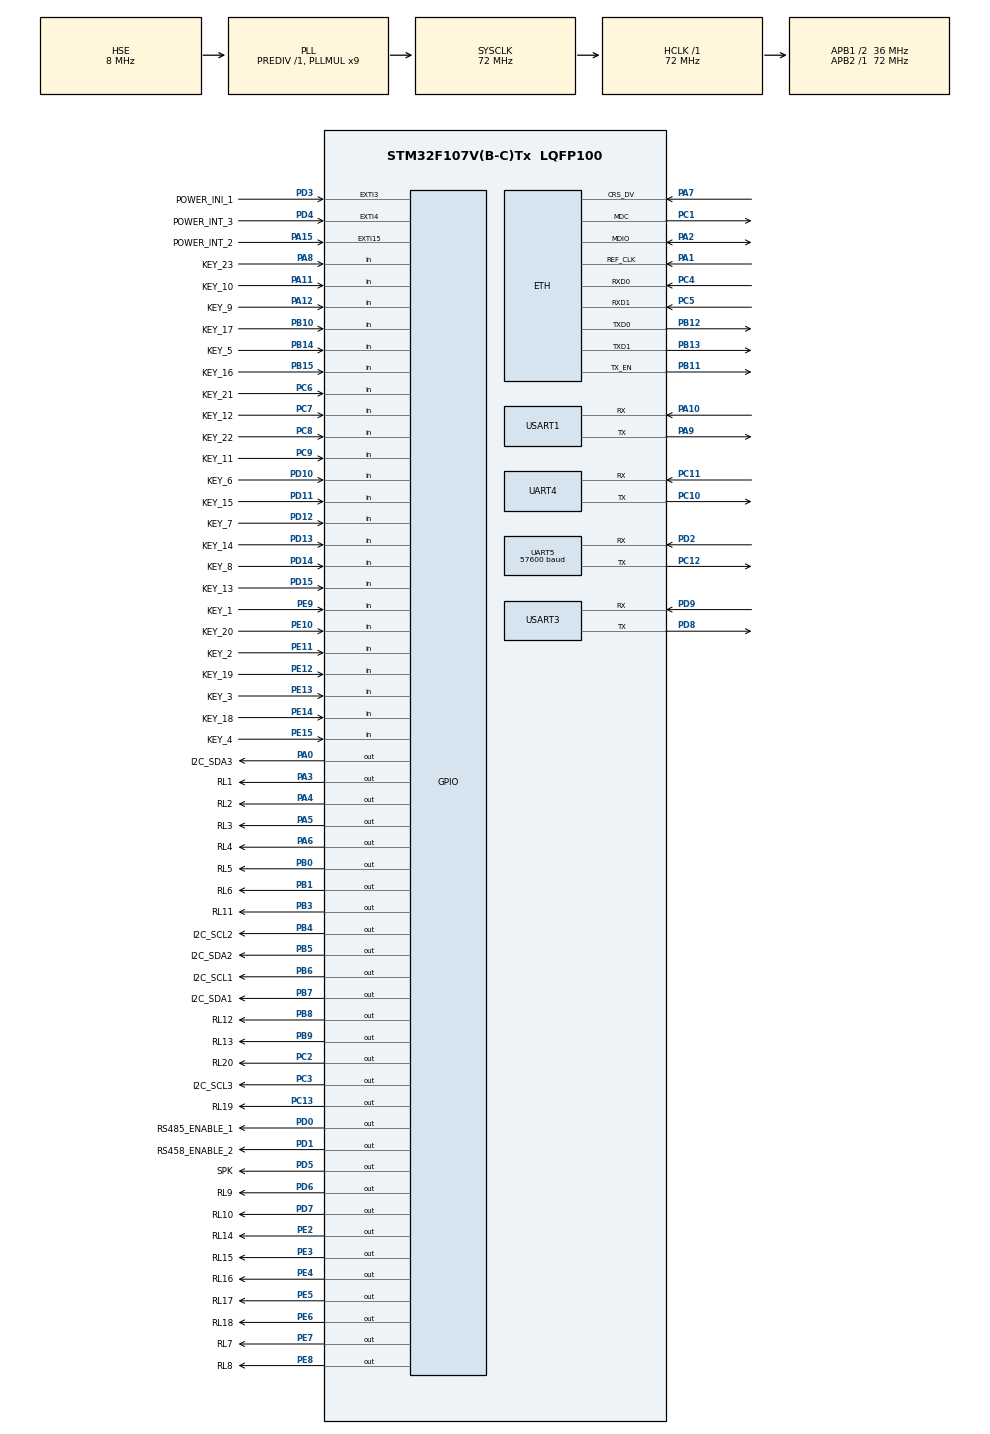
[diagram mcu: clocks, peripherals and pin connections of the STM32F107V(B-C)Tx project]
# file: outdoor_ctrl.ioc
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ETH.MediaInterface=ETH_MEDIA_INTERFACE_RMII
ETH.PhyAddress=0
FREERTOS.INCLUDE_uxTaskGetStackHighWaterMark=1
FREERTOS.INCLUDE_xTaskGetCurrentTaskHandle=1
FREERTOS.Queues01=serial_queue,8,uint8_t,NULL;socket_queue,8,uint32_t,NULL;key_queue,8,uint8_t,NULL
FREERTOS.Tasks01=system,0,200,systrm_task,Default;serial_server,2,256,serial_task,Default;socket_server,2,256,socket_server_task,Default;read_key,0,128,read_keyr_task,Default;deal_key,2,128,deal_key_task,Default
FREERTOS.configMINIMAL_STACK_SIZE=128
FREERTOS.configTOTAL_HEAP_SIZE=20480
FREERTOS.configUSE_IDLE_HOOK=1
FREERTOS.configUSE_TICK_HOOK=1
IWDG.Prescaler=IWDG_PRESCALER_16
LWIP.GATEWAY_ADDRESS=192.168.001.001
LWIP.IP_ADDRESS=192.168.001.252
LWIP.LWIP_DBG_MIN_LEVEL=LWIP_DBG_MASK_LEVEL
LWIP.LWIP_DHCP=0
LWIP.MEMP_NUM_RAW_PCB=10
LWIP.MEMP_NUM_TCP_PCB=10
LWIP.MEMP_NUM_UDP_PCB=10
LWIP.MEM_SIZE=2400
LWIP.NETMASK_ADDRESS=255.255.255.000
LWIP.TCPIP_THREAD_STACKSIZE=1024
LWIP.TCP_QUEUE_OOSEQ=0
LWIP.Version=v1.4.1_Cube
Mcu.Family=STM32F1
Mcu.Name=STM32F107V(B-C)Tx
Mcu.Package=LQFP100
NVIC.ETH_IRQn=true\:5\:0\:false\:false\:true\:true
NVIC.ETH_WKUP_IRQn=true\:5\:0\:false\:false\:true\:true
NVIC.EXTI15_10_IRQn=true\:5\:0\:false\:false\:true\:true
NVIC.EXTI3_IRQn=true\:5\:0\:false\:false\:true\:true
NVIC.EXTI4_IRQn=true\:5\:0\:false\:false\:true\:true
NVIC.PriorityGroup=NVIC_PRIORITYGROUP_4
NVIC.TIM7_IRQn=true\:0\:0\:false\:false\:true\:false
NVIC.TimeBase=TIM7_IRQn
NVIC.TimeBaseIP=TIM7
NVIC.UART5_IRQn=true\:5\:0\:false\:false\:true\:true
NVIC.USART1_IRQn=true\:5\:0\:false\:false\:true\:true
OSC_IN.Mode=HSE-External-Oscillator
OSC_IN.Signal=RCC_OSC_IN
OSC_OUT.Mode=HSE-External-Oscillator
OSC_OUT.Signal=RCC_OSC_OUT
PA0-WKUP.GPIO_Label=I2C_SDA3
PA0-WKUP.GPIO_ModeDefaultOutputPP=GPIO_MODE_OUTPUT_OD
PA0-WKUP.GPIO_Speed=GPIO_SPEED_FREQ_MEDIUM
PA0-WKUP.PinState=GPIO_PIN_SET
PA0-WKUP.Signal=GPIO_Output
PA1.Mode=RMII
PA1.Signal=ETH_REF_CLK
PA10.Mode=Asynchronous
PA10.Signal=USART1_RX
PA11.GPIO_Label=KEY_10
PA11.Signal=GPIO_Input
PA12.GPIO_Label=KEY_9
PA12.Signal=GPIO_Input
PA13.Mode=Serial_Wire
PA13.Signal=SYS_JTMS-SWDIO
PA14.Mode=Serial_Wire
PA14.Signal=SYS_JTCK-SWCLK
PA15.GPIO_Label=POWER_INT_2
PA15.GPIO_ModeDefaultEXTI=GPIO_MODE_IT_RISING
PA15.Signal=GPXTI15
PA2.Mode=RMII
PA2.Signal=ETH_MDIO
PA3.GPIO_Label=RL1
PA3.Signal=GPIO_Output
PA4.GPIO_Label=RL2
PA4.Signal=GPIO_Output
PA5.GPIO_Label=RL3
PA5.Signal=GPIO_Output
PA6.GPIO_Label=RL4
PA6.Signal=GPIO_Output
PA7.Mode=RMII
PA7.Signal=ETH_CRS_DV
PA8.GPIO_Label=KEY_23
PA8.Signal=GPIO_Input
PA9.Mode=Asynchronous
PA9.Signal=USART1_TX
PB0.GPIO_Label=RL5
PB0.Signal=GPIO_Output
PB1.GPIO_Label=RL6
PB1.Signal=GPIO_Output
PB10.GPIO_Label=KEY_17
PB10.Signal=GPIO_Input
PB11.Mode=RMII
PB11.Signal=ETH_TX_EN
PB12.Mode=RMII
PB12.Signal=ETH_TXD0
PB13.Mode=RMII
PB13.Signal=ETH_TXD1
PB14.GPIO_Label=KEY_5
PB14.Signal=GPIO_Input
PB15.GPIO_Label=KEY_16
PB15.Signal=GPIO_Input
PB3.GPIO_Label=RL11
PB3.Signal=GPIO_Output
PB4.GPIO_Label=I2C_SCL2
PB4.PinState=GPIO_PIN_SET
PB4.Signal=GPIO_Output
PB5.GPIO_Label=I2C_SDA2
PB5.GPIO_ModeDefaultOutputPP=GPIO_MODE_OUTPUT_OD
PB5.PinState=GPIO_PIN_SET
PB5.Signal=GPIO_Output
PB6.GPIO_Label=I2C_SCL1
PB6.PinState=GPIO_PIN_SET
PB6.Signal=GPIO_Output
PB7.GPIO_Label=I2C_SDA1
PB7.GPIO_ModeDefaultOutputPP=GPIO_MODE_OUTPUT_OD
PB7.PinState=GPIO_PIN_SET
PB7.Signal=GPIO_Output
PB8.GPIO_Label=RL12
PB8.Signal=GPIO_Output
PB9.GPIO_Label=RL13
PB9.Signal=GPIO_Output
PC1.Mode=RMII
PC1.Signal=ETH_MDC
PC10.Mode=Asynchronous
PC10.Signal=UART4_TX
PC11.Mode=Asynchronous
PC11.Signal=UART4_RX
PC12.Mode=Asynchronous
PC12.Signal=UART5_TX
PC13-TAMPER-RTC.GPIO_Label=RL19
PC13-TAMPER-RTC.Signal=GPIO_Output
PC14-OSC32_IN.Mode=LSE-External-Oscillator
PC14-OSC32_IN.Signal=RCC_OSC32_IN
PC15-OSC32_OUT.Mode=LSE-External-Oscillator
PC15-OSC32_OUT.Signal=RCC_OSC32_OUT
PC2.GPIO_Label=RL20
PC2.Signal=GPIO_Output
PC3.GPIO_Label=I2C_SCL3
PC3.PinState=GPIO_PIN_SET
PC3.Signal=GPIO_Output
PC4.Mode=RMII
PC4.Signal=ETH_RXD0
PC5.Mode=RMII
PC5.Signal=ETH_RXD1
PC6.GPIO_Label=KEY_21
PC6.Signal=GPIO_Input
PC7.GPIO_Label=KEY_12
PC7.Signal=GPIO_Input
PC8.GPIO_Label=KEY_22
PC8.Signal=GPIO_Input
PC9.GPIO_Label=KEY_11
PC9.Signal=GPIO_Input
PD0.GPIO_Label=RS485_ENABLE_1
PD0.Signal=GPIO_Output
PD1.GPIO_Label=RS458_ENABLE_2
PD1.Signal=GPIO_Output
PD10.GPIO_Label=KEY_6
PD10.Signal=GPIO_Input
PD11.GPIO_Label=KEY_15
PD11.Signal=GPIO_Input
PD12.GPIO_Label=KEY_7
PD12.Signal=GPIO_Input
PD13.GPIO_Label=KEY_14
PD13.Signal=GPIO_Input
PD14.GPIO_Label=KEY_8
PD14.Signal=GPIO_Input
PD15.GPIO_Label=KEY_13
PD15.Signal=GPIO_Input
PD2.Mode=Asynchronous
PD2.Signal=UART5_RX
PD3.GPIO_Label=POWER_INI_1
PD3.Signal=GPXTI3
PD4.GPIO_Label=POWER_INT_3
PD4.Signal=GPXTI4
PD5.GPIO_Label=SPK
PD5.Signal=GPIO_Output
PD6.GPIO_Label=RL9
PD6.Signal=GPIO_Output
PD7.GPIO_Label=RL10
PD7.Signal=GPIO_Output
PD8.Mode=Asynchronous
PD8.Signal=USART3_TX
PD9.Mode=Asynchronous
PD9.Signal=USART3_RX
PE10.GPIO_Label=KEY_20
PE10.Signal=GPIO_Input
PE11.GPIO_Label=KEY_2
PE11.Signal=GPIO_Input
PE12.GPIO_Label=KEY_19
PE12.Signal=GPIO_Input
PE13.GPIO_Label=KEY_3
PE13.Signal=GPIO_Input
PE14.GPIO_Label=KEY_18
PE14.Signal=GPIO_Input
PE15.GPIO_Label=KEY_4
PE15.Signal=GPIO_Input
PE2.GPIO_Label=RL14
PE2.Signal=GPIO_Output
PE3.GPIO_Label=RL15
PE3.Signal=GPIO_Output
PE4.GPIO_Label=RL16
PE4.Signal=GPIO_Output
PE5.GPIO_Label=RL17
PE5.Signal=GPIO_Output
PE6.GPIO_Label=RL18
PE6.Signal=GPIO_Output
PE7.GPIO_Label=RL7
PE7.Signal=GPIO_Output
PE8.GPIO_Label=RL8
PE8.Signal=GPIO_Output
PE9.GPIO_Label=KEY_1
PE9.Signal=GPIO_Input
ProjectManager.HeapSize=0x1000
ProjectManager.StackSize=0x800
ProjectManager.TargetToolchain=MDK-ARM V5
RCC.AHBFreq_Value=72000000
RCC.APB1CLKDivider=RCC_HCLK_DIV2
RCC.APB1Freq_Value=36000000
RCC.APB1TimFreq_Value=72000000
RCC.APB2Freq_Value=72000000
RCC.APB2TimFreq_Value=72000000
RCC.HCLKFreq_Value=72000000
RCC.HSIState=RCC_HSI_ON
RCC.PLLMUL=RCC_PLL_MUL9
RCC.PLLSourceVirtual=RCC_PLLSOURCE_HSE
RCC.SYSCLKFreq_VALUE=72000000
RCC.SYSCLKSource=RCC_SYSCLKSOURCE_PLLCLK
RCC.USBFreq_Value=48000000
TIM1.Period=999
TIM1.Prescaler=71
TIM2.Period=999
TIM2.Prescaler=72
TIM3.Period=999
TIM3.Prescaler=71
TIM4.Period=999
TIM4.Prescaler=71
TIM5.CounterMode=TIM_COUNTERMODE_DOWN
TIM5.Period=999
TIM5.Prescaler=71
TIM6.Period=999
TIM6.Prescaler=71
UART5.BaudRate=57600
VP_FREERTOS_VS_ENABLE.Mode=Enabled
VP_IWDG_VS_IWDG.Mode=IWDG_Activate
VP_LWIP_VS_Enabled.Mode=Enabled
VP_SYS_VS_tim7.Mode=TIM7
VP_TIM1_VS_ClockSourceINT.Mode=Internal
VP_TIM2_VS_ClockSourceINT.Mode=Internal
VP_TIM3_VS_ClockSourceINT.Mode=Internal
VP_TIM4_VS_ClockSourceINT.Mode=Internal
VP_TIM5_VS_ClockSourceINT.Mode=Internal
VP_TIM6_VS_ClockSourceINT.Mode=Enable_Timer
board=outdoor_ctrl

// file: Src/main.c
/**
  ******************************************************************************
  * File Name          : main.c
  * Description        : Main program body
  ******************************************************************************
  *
  * COPYRIGHT(c) 2017 STMicroelectronics
  *
  * Redistribution and use in source and binary forms, with or without modification,
  * are permitted provided that the following conditions are met:
  *   1. Redistributions of source code must retain the above copyright notice,
  *      this list of conditions and the following disclaimer.
  *   2. Redistributions in binary form must reproduce the above copyright notice,
  *      this list of conditions and the following disclaimer in the documentation
  *      and/or other materials provided with the distribution.
  *   3. Neither the name of STMicroelectronics nor the names of its contributors
  *      may be used to endorse or promote products derived from this software
  *      without specific prior written permission.
  *
  * THIS SOFTWARE IS PROVIDED BY THE COPYRIGHT HOLDERS AND CONTRIBUTORS "AS IS"
  * AND ANY EXPRESS OR IMPLIED WARRANTIES, INCLUDING, BUT NOT LIMITED TO, THE
  * IMPLIED WARRANTIES OF MERCHANTABILITY AND FITNESS FOR A PARTICULAR PURPOSE ARE
  * DISCLAIMED. IN NO EVENT SHALL THE COPYRIGHT HOLDER OR CONTRIBUTORS BE LIABLE
  * FOR ANY DIRECT, INDIRECT, INCIDENTAL, SPECIAL, EXEMPLARY, OR CONSEQUENTIAL
  * DAMAGES (INCLUDING, BUT NOT LIMITED TO, PROCUREMENT OF SUBSTITUTE GOODS OR
  * SERVICES; LOSS OF USE, DATA, OR PROFITS; OR BUSINESS INTERRUPTION) HOWEVER
  * CAUSED AND ON ANY THEORY OF LIABILITY, WHETHER IN CONTRACT, STRICT LIABILITY,
  * OR TORT (INCLUDING NEGLIGENCE OR OTHERWISE) ARISING IN ANY WAY OUT OF THE USE
  * OF THIS SOFTWARE, EVEN IF ADVISED OF THE POSSIBILITY OF SUCH DAMAGE.
  *
  ******************************************************************************
  */
#include "stm32f1xx_hal.h"
#include "cmsis_os.h"
#include "iwdg.h"
#include "lwip.h"
#include "tim.h"
#include "usart.h"
#include "gpio.h"

/* USER CODE BEGIN Includes */
#include "include.h"
/* USER CODE END Includes */

/* USER CODE BEGIN PV */
/* Private variables ---------------------------------------------------------*/

/* USER CODE END PV */

void SystemClock_Config(void);
void Error_Handler(void);
void MX_FREERTOS_Init(void);

/* USER CODE BEGIN PFP */
/* Private function prototypes -----------------------------------------------*/

#define COM huart1  //重定向到串口

#ifdef __GNUC__
  /* With GCC/RAISONANCE, small printf (option LD Linker->Libraries->Small printf
     set to 'Yes') calls __io_putchar() */
  #define PUTCHAR_PROTOTYPE int __io_putchar(int ch)
#else
  #define PUTCHAR_PROTOTYPE int fputc(int ch, FILE *f)
#endif /* __GNUC__ */
/**
  * @brief  Retargets the C library printf function to the USART.
  * @param  None
  * @retval None
  */
PUTCHAR_PROTOTYPE
{
  /* Place your implementation of fputc here */
  /* e.g. write a character to the EVAL_COM1 and Loop until the end of transmission */
  HAL_UART_Transmit(&COM, (unsigned char *)&ch, 1, 0xFFFF);

  return ch;
}

void test_timer_call_back(void* arg)
{
	unsigned int num;
	num = (int)arg;
	printf("timer %d over flow\n\r",num);
}
/* USER CODE END PFP */

/* USER CODE BEGIN 0 */
unsigned int phyreg;
/* USER CODE END 0 */

int main(void)
{

  /* MCU Configuration----------------------------------------------------------*/

  /* Reset of all peripherals, Initializes the Flash interface and the Systick. */
  HAL_Init();

  /* Configure the system clock */
  SystemClock_Config();

  /* Initialize all configured peripherals */
  MX_GPIO_Init();
  MX_UART4_Init();
  MX_UART5_Init();
  MX_USART1_UART_Init();
  MX_USART3_UART_Init();
  MX_IWDG_Init();
  MX_TIM1_Init();
  MX_TIM2_Init();
  MX_TIM3_Init();
  MX_TIM4_Init();
  MX_TIM5_Init();
  MX_TIM6_Init();

  /* USER CODE BEGIN 2 */
	//HAL_ETH_ReadPHYRegister(&heth, 0, &phyreg);
	//HAL_ETH_ReadPHYRegister(&heth, 1, &phyreg);
	//HAL_ETH_ReadPHYRegister(&heth, 2, &phyreg);
	//HAL_ETH_ReadPHYRegister(&heth, 3, &phyreg);

	#if WATCH_DOG
	HAL_IWDG_Start(&hiwdg);
	#endif

	HAL_TIM_Base_Start_IT(&htim5);
	//register_value_into_timer(2000,1);
	register_callback_function_into_timer(register_value_into_timer(2000,1),test_timer_call_back);
	register_value_into_timer(1000,1);
	register_value_into_timer(1000,0);
	timer_free(1);
	register_value_into_timer(3000,0);
	register_value_into_timer(5000,1);

	register_callback_function_into_timer(register_value_into_timer(3000,1),test_timer_call_back);

	register_callback_function_into_timer(register_value_into_timer(2000,1),test_timer_call_back);

	register_callback_function_into_timer(register_value_into_timer(1000,1),test_timer_call_back);

  /* USER CODE END 2 */

  /* Call init function for freertos objects (in freertos.c) */
  MX_FREERTOS_Init();

  /* Start scheduler */
  osKernelStart();

  /* We should never get here as control is now taken by the scheduler */

  /* Infinite loop */
  while (1)
  {

  /* USER CODE BEGIN 3 */
  //MX_LWIP_Process();

  }
  /* USER CODE END 3 */

}

/** System Clock Configuration
*/
void SystemClock_Config(void)
{

  RCC_OscInitTypeDef RCC_OscInitStruct;
  RCC_ClkInitTypeDef RCC_ClkInitStruct;

  RCC_OscInitStruct.OscillatorType = RCC_OSCILLATORTYPE_LSI|RCC_OSCILLATORTYPE_HSE;
  RCC_OscInitStruct.HSEState = RCC_HSE_ON;
  RCC_OscInitStruct.HSEPredivValue = RCC_HSE_PREDIV_DIV1;
  RCC_OscInitStruct.LSIState = RCC_LSI_ON;
  RCC_OscInitStruct.Prediv1Source = RCC_PREDIV1_SOURCE_HSE;
  RCC_OscInitStruct.PLL.PLLState = RCC_PLL_ON;
  RCC_OscInitStruct.PLL.PLLSource = RCC_PLLSOURCE_HSE;
  RCC_OscInitStruct.PLL.PLLMUL = RCC_PLL_MUL9;
  RCC_OscInitStruct.PLL2.PLL2State = RCC_PLL_NONE;
  if (HAL_RCC_OscConfig(&RCC_OscInitStruct) != HAL_OK)
  {
    Error_Handler();
  }

  RCC_ClkInitStruct.ClockType = RCC_CLOCKTYPE_HCLK|RCC_CLOCKTYPE_SYSCLK
                              |RCC_CLOCKTYPE_PCLK1|RCC_CLOCKTYPE_PCLK2;
  RCC_ClkInitStruct.SYSCLKSource = RCC_SYSCLKSOURCE_PLLCLK;
  RCC_ClkInitStruct.AHBCLKDivider = RCC_SYSCLK_DIV1;
  RCC_ClkInitStruct.APB1CLKDivider = RCC_HCLK_DIV2;
  RCC_ClkInitStruct.APB2CLKDivider = RCC_HCLK_DIV1;
  if (HAL_RCC_ClockConfig(&RCC_ClkInitStruct, FLASH_LATENCY_2) != HAL_OK)
  {
    Error_Handler();
  }

  HAL_SYSTICK_Config(HAL_RCC_GetHCLKFreq()/1000);

  HAL_SYSTICK_CLKSourceConfig(SYSTICK_CLKSOURCE_HCLK);

  __HAL_RCC_PLLI2S_ENABLE();

  /* SysTick_IRQn interrupt configuration */
  HAL_NVIC_SetPriority(SysTick_IRQn, 15, 0);
}

void HAL_TIM_PeriodElapsedCallback(TIM_HandleTypeDef *htim)
{
/* USER CODE BEGIN Callback 0 */

	if (htim->Instance == TIM5) {
		INC_COUNTER_TIMER();
	}
/* USER CODE END Callback 0 */
  if (htim->Instance == TIM7) {
    HAL_IncTick();
  }
}

void Error_Handler(void)
{
  while(1)
  {
  }
}

/************************ (C) COPYRIGHT STMicroelectronics *****END OF FILE****/

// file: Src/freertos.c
/**
  ******************************************************************************
  * File Name          : freertos.c
  * Description        : Code for freertos applications
  ******************************************************************************
  *
  * COPYRIGHT(c) 2017 STMicroelectronics
  *
  * Redistribution and use in source and binary forms, with or without modification,
  * are permitted provided that the following conditions are met:
  *   1. Redistributions of source code must retain the above copyright notice,
  *      this list of conditions and the following disclaimer.
  *   2. Redistributions in binary form must reproduce the above copyright notice,
  *      this list of conditions and the following disclaimer in the documentation
  *      and/or other materials provided with the distribution.
  *   3. Neither the name of STMicroelectronics nor the names of its contributors
  *      may be used to endorse or promote products derived from this software
  *      without specific prior written permission.
  *
  * THIS SOFTWARE IS PROVIDED BY THE COPYRIGHT HOLDERS AND CONTRIBUTORS "AS IS"
  * AND ANY EXPRESS OR IMPLIED WARRANTIES, INCLUDING, BUT NOT LIMITED TO, THE
  * IMPLIED WARRANTIES OF MERCHANTABILITY AND FITNESS FOR A PARTICULAR PURPOSE ARE
  * DISCLAIMED. IN NO EVENT SHALL THE COPYRIGHT HOLDER OR CONTRIBUTORS BE LIABLE
  * FOR ANY DIRECT, INDIRECT, INCIDENTAL, SPECIAL, EXEMPLARY, OR CONSEQUENTIAL
  * DAMAGES (INCLUDING, BUT NOT LIMITED TO, PROCUREMENT OF SUBSTITUTE GOODS OR
  * SERVICES; LOSS OF USE, DATA, OR PROFITS; OR BUSINESS INTERRUPTION) HOWEVER
  * CAUSED AND ON ANY THEORY OF LIABILITY, WHETHER IN CONTRACT, STRICT LIABILITY,
  * OR TORT (INCLUDING NEGLIGENCE OR OTHERWISE) ARISING IN ANY WAY OUT OF THE USE
  * OF THIS SOFTWARE, EVEN IF ADVISED OF THE POSSIBILITY OF SUCH DAMAGE.
  *
  ******************************************************************************
  */

#include "FreeRTOS.h"
#include "task.h"
#include "cmsis_os.h"

/* USER CODE BEGIN Includes */
#include "lwip/opt.h"
#include "lwip/def.h"
#include "lwip/ip_addr.h"
//#include "lwip/ip6_addr.h"
#include "lwip/sockets.h"
#include "include.h"
#include "stats.h"
/* USER CODE END Includes */

osThreadId systemHandle;
osThreadId serial_serverHandle;
osThreadId socket_serverHandle;
osThreadId read_keyHandle;
osThreadId deal_keyHandle;
osThreadId relay_serverHandle;
osThreadId watcherHandle;
osMessageQId serial_queueHandle;
osMessageQId socket_queueHandle;
osMessageQId key_queueHandle;

/* USER CODE BEGIN Variables */
osMessageQId relay_queueHandle;

unsigned char g_recv_buf[3][500];
extern IWDG_HandleTypeDef hiwdg;
extern struct stats_ lwip_stats;
/* USER CODE END Variables */

void system_task(void const * argument);
void serial_task(void const * argument);
void socket_server_task(void const * argument);
void read_key_task(void const * argument);
void deal_key_task(void const * argument);
void relay_task(void const * argument);
void watcher_task(void const * argument);

extern void MX_LWIP_Init(void);
void MX_FREERTOS_Init(void); /* (MISRA C 2004 rule 8.1) */

/* Hook prototypes */
void vApplicationIdleHook(void);
void vApplicationTickHook(void);

/* Init FreeRTOS */

void MX_FREERTOS_Init(void) {

  /* Create the thread(s) */
  /* definition and creation of system */
  osThreadDef(system, system_task, osPriorityNormal, 0, 200);
  systemHandle = osThreadCreate(osThread(system), NULL);

  /* definition and creation of serial_server */
  osThreadDef(serial_server, serial_task, osPriorityHigh, 0, 256);
  serial_serverHandle = osThreadCreate(osThread(serial_server), NULL);

  /* definition and creation of socket_server */
  osThreadDef(socket_server, socket_server_task, osPriorityHigh, 0, 256);
  socket_serverHandle = osThreadCreate(osThread(socket_server), NULL);

  /* definition and creation of read_key */
  osThreadDef(read_key, read_key_task, osPriorityNormal, 0, 128);
  read_keyHandle = osThreadCreate(osThread(read_key), NULL);

  /* definition and creation of deal_key */
  osThreadDef(deal_key, deal_key_task, osPriorityHigh, 0, 128);
  deal_keyHandle = osThreadCreate(osThread(deal_key), NULL);

  /* definition and creation of relay_server */
  osThreadDef(relay_server, relay_task, osPriorityHigh, 0, 128);
  relay_serverHandle = osThreadCreate(osThread(relay_server), NULL);

  /* definition and creation of watcher */
  osThreadDef(watcher, watcher_task, osPriorityNormal, 0, 128);
  watcherHandle = osThreadCreate(osThread(watcher), NULL);

  /* Create the queue(s) */
  /* definition and creation of serial_queue */
  osMessageQDef(serial_queue, 8, uint8_t);
  serial_queueHandle = osMessageCreate(osMessageQ(serial_queue), NULL);

  /* definition and creation of socket_queue */
  osMessageQDef(socket_queue, 8, uint32_t);
  socket_queueHandle = osMessageCreate(osMessageQ(socket_queue), NULL);

  /* definition and creation of key_queue */
  osMessageQDef(key_queue, 8, uint8_t);
  key_queueHandle = osMessageCreate(osMessageQ(key_queue), NULL);

  /* USER CODE BEGIN RTOS_QUEUES */
  /* add queues, ... */
  osMessageQDef(relay_queue, 8, uint32_t);
  relay_queueHandle = osMessageCreate(osMessageQ(relay_queue), NULL);
  /* USER CODE END RTOS_QUEUES */
}

/* system_task function */
void system_task(void const * argument)
{
  /* init code for LWIP */
  MX_LWIP_Init();

  for(;;)
  {
    osDelay(1);
  }
}

/* serial_task function */
void serial_task(void const * argument)
{
  /* USER CODE BEGIN serial_task */
	save_task_info();

  osDelay(2000);

	register_queue_into_timer(register_value_into_timer(1200,0),relay_queueHandle);
	register_queue_into_timer(register_value_into_timer(2000,0),relay_queueHandle);

  //static unsigned int recvdata = 0;
  P_S_Socket_Task_Info client_socket;
  client_socket = (P_S_Socket_Task_Info)malloc(sizeof(S_Socket_Task_Info));

  sprintf(client_socket->target_server_ip,"192.168.1.172");
  client_socket->target_server_port = 5566;
  client_socket->task_signal = socket_queueHandle;
  //client_socket->recv_buf = g_recv_buf;

  socket_creat_client_task("client_task_a",client_socket);

  osDelay(1000);
  P_S_Socket_Task_Info client_socket1;
  client_socket1 = (P_S_Socket_Task_Info)malloc(sizeof(S_Socket_Task_Info));

  sprintf(client_socket1->target_server_ip,"192.168.1.172");
  client_socket1->target_server_port = 5566;
  client_socket1->task_signal = socket_queueHandle;
  //client_socket1->recv_buf = g_recv_buf;

  socket_creat_client_task("client_task_b",client_socket1);

  /* osDelay(1000);
  P_S_Socket_Task_Info client_socket2;
  client_socket2 = (P_S_Socket_Task_Info)malloc(sizeof(S_Socket_Task_Info));

  sprintf(client_socket2->target_server_ip,"192.168.1.179");
  client_socket2->target_server_port = 5566;
  client_socket2->task_signal = socket_queueHandle;
  client_socket2->recv_buf = g_recv_buf;

  socket_creat_client_task("client_task_c",client_socket2);

  osDelay(1000);
  P_S_Socket_Task_Info client_socket3;
  client_socket3 = (P_S_Socket_Task_Info)malloc(sizeof(S_Socket_Task_Info));

  sprintf(client_socket3->target_server_ip,"192.168.1.179");
  client_socket3->target_server_port = 5566;
  client_socket3->task_signal = socket_queueHandle;
  client_socket3->recv_buf = g_recv_buf;

  socket_creat_client_task("client_task_d",client_socket3);*/

   /*osDelay(1000);
  P_S_Socket_Task_Info client_socket4;
  client_socket4 = (P_S_Socket_Task_Info)malloc(sizeof(S_Socket_Task_Info));

  sprintf(client_socket4->target_server_ip,"192.168.1.179");
  client_socket4->target_server_port = 5566;
  client_socket4->recv_buf = g_recv_buf;

  socket_creat_client_task("client_task_e",client_socket4);*/

  osDelay(1000);

  //socket_tcp_server_task((void*)1111);

  P_S_Socket_Task_Info server_socket;
  server_socket = (P_S_Socket_Task_Info)malloc(sizeof(S_Socket_Task_Info));

  server_socket->port = 5566;
  server_socket->task_signal = socket_queueHandle;
  server_socket->recv_buf = g_recv_buf[0];
  server_socket->buf_length = 500;
  socket_creat_server_task("server_task_1",server_socket);

  osDelay(1000);
  P_S_Socket_Task_Info server_socket2;
  server_socket2 = (P_S_Socket_Task_Info)malloc(sizeof(S_Socket_Task_Info));

  server_socket2->port = 1111;
  server_socket2->task_signal = socket_queueHandle;
  server_socket2->recv_buf = g_recv_buf[1];
  server_socket2->buf_length = 500;
  socket_creat_server_task("server_task_2",server_socket2);

  osDelay(1000);
  P_S_Socket_Task_Info server_socket3;
  server_socket3 = (P_S_Socket_Task_Info)malloc(sizeof(S_Socket_Task_Info));

  server_socket3->port = 1234;
  server_socket3->task_signal = socket_queueHandle;
  server_socket3->recv_buf = g_recv_buf[2];
  server_socket3->buf_length = 500;
  socket_creat_server_task("server_task_3",server_socket3);

  /* osDelay(1000);
  P_S_Socket_Task_Info client_socket5;
  client_socket5 = (P_S_Socket_Task_Info)malloc(sizeof(S_Socket_Task_Info));
  socket_creat_client("client_task_f",client_socket5);

   osDelay(1000);
  P_S_Socket_Task_Info client_socket6;
  client_socket6 = (P_S_Socket_Task_Info)malloc(sizeof(S_Socket_Task_Info));
  socket_creat_client("client_task_g",client_socket6);*/

  /* Infinite loop */
  for(;;)
  {
	//xQueueReceive(socket_queueHandle, &recvdata, portMAX_DELAY);

  	osDelay(100);
  }
  /* USER CODE END serial_task */
}

/* socket_server_task function */
void socket_server_task(void const * argument)
{
  /* USER CODE BEGIN socket_server_task */
	save_task_info();
  	osDelay(12000);

  /* Infinite loop */
  for(;;)
  {
  	osDelay(2000);
	//stats_display_sys(&lwip_stats.sys);
	//stats_display();
	  //printf(("\nSYS\n\t"));
	  //printf("sem.used:  %d\n\r", (u32_t)lwip_stats.sys.sem.used);
	  //printf("sem.max:   %d\n\r", (u32_t)lwip_stats.sys.sem.max);
	  //printf("sem.err:   %d\n\r", (u32_t)lwip_stats.sys.sem.err);
	 // printf("mutex.used: %d\n\r", (u32_t)lwip_stats.sys.mutex.used);
	 // printf("mutex.max:  %d\n\r", (u32_t)lwip_stats.sys.mutex.max);
	  //printf("mutex.err:  %d\n\r", (u32_t)lwip_stats.sys.mutex.err);
	  //printf("mbox.used:  %d\n\r", (u32_t)lwip_stats.sys.mbox.used);
	 // printf("mbox.max:   %d\n\r", (u32_t)lwip_stats.sys.mbox.max);
	 // printf("mbox.err:   %d\n\r", (u32_t)lwip_stats.sys.mbox.err);
  }
  /* USER CODE END socket_server_task */
}

/* read_key_task function */
void read_key_task(void const * argument)
{
  for(;;)
  {
    osDelay(1);
  }
}

/* deal_key_task function */
void deal_key_task(void const * argument)
{
  /* USER CODE BEGIN deal_key_task */
  	save_task_info();
	unsigned char recv_key_value;
  /* Infinite loop */
  for(;;)
  {
	xQueueReceive(key_queueHandle, &recv_key_value, portMAX_DELAY);
	deal_key_value(recv_key_value);
   }
  /* USER CODE END deal_key_task */
}

/* relay_task function */
void relay_task(void const * argument)
{
  /* USER CODE BEGIN relay_task */
	save_task_info();
	unsigned int recv_relay_value;
  /* Infinite loop */
  for(;;)
  {
	xQueueReceive(relay_queueHandle, &recv_relay_value, portMAX_DELAY);
	deal_key_value(recv_relay_value);
   }
  /* USER CODE END relay_task */
}

/* watcher_task function */
void watcher_task(void const * argument)
{
  for(;;)
  {
    osDelay(1);
  }
}

/************************ (C) COPYRIGHT STMicroelectronics *****END OF FILE****/
